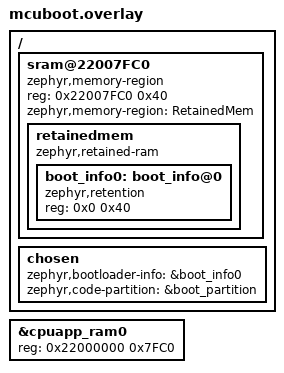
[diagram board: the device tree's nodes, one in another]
/ {
	sram@22007FC0 {
		compatible = "zephyr,memory-region", "mmio-sram";
		reg = <0x22007FC0 0x40>;
		zephyr,memory-region = "RetainedMem";
		status = "okay";

		retainedmem {
			compatible = "zephyr,retained-ram";
			status = "okay";
			#address-cells = <1>;
			#size-cells = <1>;

			boot_info0: boot_info@0 {
				compatible = "zephyr,retention";
				status = "okay";
				reg = <0x0 0x40>;
			};
		};
	};

	chosen {
		zephyr,bootloader-info = &boot_info0;
		zephyr,code-partition = &boot_partition;
	};
};

&cpuapp_ram0 {
	reg = <0x22000000 0x7FC0>;
};
